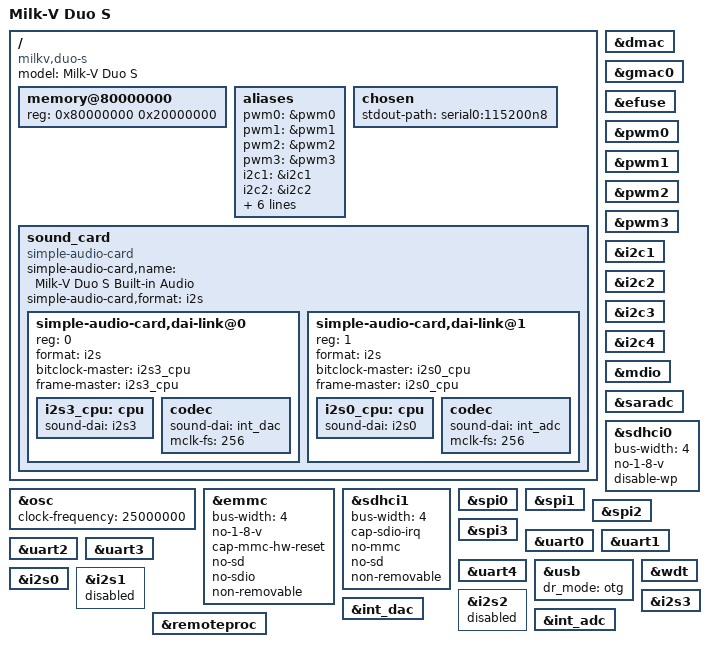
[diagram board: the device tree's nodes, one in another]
// SPDX-License-Identifier: (GPL-2.0 OR MIT)

/dts-v1/;

#include "sg2000.dtsi"

/ {
	model = "Milk-V Duo S";
	compatible = "milkv,duo-s", "sophgo,sg2000";

	memory@80000000 {
		device_type = "memory";
		reg = <0x80000000 0x20000000>;
	};

	aliases {
		pwm0 = &pwm0;
		pwm1 = &pwm1;
		pwm2 = &pwm2;
		pwm3 = &pwm3;
		i2c1 = &i2c1;
		i2c2 = &i2c2;
		i2c3 = &i2c3;
		i2c4 = &i2c4;
		mmc0 = &sdhci0;
		serial0 = &uart0;
		spi0 = &spi0;
		spi3 = &spi3;
	};

	chosen {
		stdout-path = "serial0:115200n8";
	};

	sound_card {
		compatible = "simple-audio-card";
		simple-audio-card,name = "Milk-V Duo S Built-in Audio";
		simple-audio-card,format = "i2s";

		#address-cells = <1>;
		#size-cells = <0>;

		simple-audio-card,dai-link@0 {
			reg = <0>;
			format = "i2s";
			bitclock-master = <&i2s3_cpu>;
			frame-master = <&i2s3_cpu>;

			i2s3_cpu: cpu {
				sound-dai = <&i2s3>;
			};
			codec {
				sound-dai = <&int_dac>;
				mclk-fs = <256>;
			};
		};

		simple-audio-card,dai-link@1 {
			reg = <1>;
			format = "i2s";
			bitclock-master = <&i2s0_cpu>;
			frame-master = <&i2s0_cpu>;

			i2s0_cpu: cpu {
				sound-dai = <&i2s0>;
			};
			codec {
				sound-dai = <&int_adc>;
				mclk-fs = <256>;
			};
		};
	};
};

&osc {
	clock-frequency = <25000000>;
};

&dmac {
	status = "okay";
};

&emmc {
	bus-width = <4>;
	no-1-8-v;
	cap-mmc-hw-reset;
	no-sd;
	no-sdio;
	non-removable;
	status = "okay";
};

&gmac0 {
	status = "okay";
};

&efuse {
	status = "okay";
};

&pwm0 {
	status = "okay";
};

&pwm1 {
	status = "okay";
};

&pwm2 {
	status = "okay";
};

&pwm3 {
	status = "okay";
};

&i2c1 {
	status = "okay";
};

&i2c2 {
	status = "okay";
};

&i2c3 {
	status = "okay";
};

&i2c4 {
	status = "okay";
};

&mdio {
	status = "okay";
};

&saradc {
	status = "okay";
};

&sdhci0 {
	bus-width = <4>;
	no-1-8-v;
	disable-wp;
	status = "okay";
};

&sdhci1 {
	bus-width = <4>;
	cap-sdio-irq;
	no-mmc;
	no-sd;
	non-removable;
	status = "okay";
};

&spi0 {
	status = "okay";
};

&spi1 {
	status = "okay";
};

&spi2 {
	status = "okay";
};

&spi3 {
	status = "okay";
};

&uart0 {
	status = "okay";
};

&uart1 {
	status = "okay";
};

&uart2 {
	status = "okay";
};

&uart3 {
	status = "okay";
};

&uart4 {
	status = "okay";
};

&usb {
	dr_mode = "otg";
	status = "okay";
};

&wdt {
	status = "okay";
};

&i2s0 {
	status = "okay";
	#sound-dai-cells = <0>;
};

&i2s1 {
	status = "disabled";
};

&i2s2 {
	status = "disabled";
};

&i2s3 {
	status = "okay";
	#sound-dai-cells = <0>;
};

&int_dac {
	status = "okay";
};

&int_adc {
	status = "okay";
	#sound-dai-cells = <0>;
	/delete-property/ mute-gpio-l;
	/delete-property/ mute-gpio-r;
};

&remoteproc {
	status = "okay";
};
